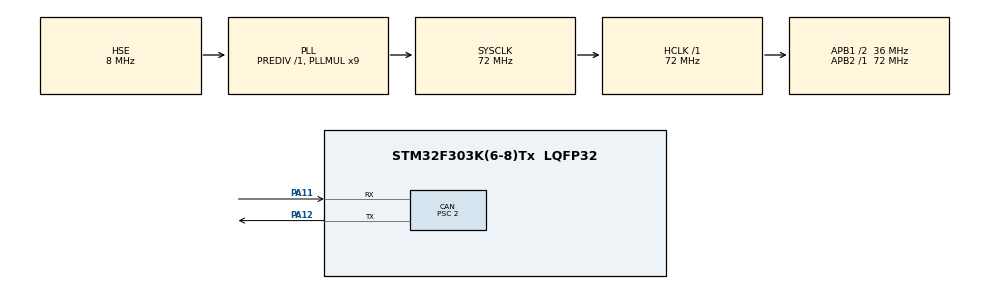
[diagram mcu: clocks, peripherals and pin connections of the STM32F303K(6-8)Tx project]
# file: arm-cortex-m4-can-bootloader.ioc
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CAN.BS1=CAN_BS1_14TQ
CAN.BS2=CAN_BS2_3TQ
CAN.CalculateBaudRate=1000000
CAN.CalculateTimeBit=1000
CAN.CalculateTimeQuantum=55.55555555555556
CAN.Prescaler=2
Mcu.Family=STM32F3
Mcu.Name=STM32F303K(6-8)Tx
Mcu.Package=LQFP32
NVIC.CAN_RX0_IRQn=true\:0\:0\:false\:false\:true\:true\:true\:true
NVIC.PriorityGroup=NVIC_PRIORITYGROUP_4
PA11.Mode=CAN_Activate
PA11.Signal=CAN_RX
PA12.Mode=CAN_Activate
PA12.Signal=CAN_TX
PA13.Mode=Serial_Wire
PA13.Signal=SYS_JTMS-SWDIO
PA14.Mode=Serial_Wire
PA14.Signal=SYS_JTCK-SWCLK
PF0\ /\ OSC_IN.Mode=HSE-External-Oscillator
PF0\ /\ OSC_IN.Signal=RCC_OSC_IN
PF1\ /\ OSC_OUT.Mode=HSE-External-Oscillator
PF1\ /\ OSC_OUT.Signal=RCC_OSC_OUT
ProjectManager.HeapSize=0x200
ProjectManager.StackSize=0x400
ProjectManager.TargetToolchain=CMake
RCC.AHBFreq_Value=72000000
RCC.APB1CLKDivider=RCC_HCLK_DIV2
RCC.APB1Freq_Value=36000000
RCC.APB1TimFreq_Value=72000000
RCC.APB2Freq_Value=72000000
RCC.APB2TimFreq_Value=72000000
RCC.CortexFreq_Value=72000000
RCC.HCLKFreq_Value=72000000
RCC.HSE_VALUE=8000000
RCC.HSI_VALUE=8000000
RCC.PLLMUL=RCC_PLL_MUL9
RCC.PLLSourceVirtual=RCC_PLLSOURCE_HSE
RCC.SYSCLKFreq_VALUE=72000000
RCC.SYSCLKSourceVirtual=RCC_SYSCLKSOURCE_PLLCLK
VP_CRC_VS_CRC.Mode=CRC_Activate
board=custom

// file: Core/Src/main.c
/* USER CODE BEGIN Header */
/**
 ******************************************************************************
 * @file           : main.c
 * @brief          : Main program body
 ******************************************************************************
 * @attention
 *
 * Copyright (c) 2026 STMicroelectronics.
 * All rights reserved.
 *
 * This software is licensed under terms that can be found in the LICENSE file
 * in the root directory of this software component.
 * If no LICENSE file comes with this software, it is provided AS-IS.
 *
 ******************************************************************************
 */
/* USER CODE END Header */
#include "main.h"

/* USER CODE BEGIN Includes */
#include "bootloader.h"
#include "can_protocol.h"
#include "stm32f3xx_it.h"
#include <stdint.h>
/* USER CODE END Includes */

CAN_HandleTypeDef hcan;

CRC_HandleTypeDef hcrc;

void SystemClock_Config(void);
static void MX_GPIO_Init(void);
static void MX_CRC_Init(void);
static void MX_CAN_Init(void);

int main(void) {

  /* MCU Configuration--------------------------------------------------------*/

  /* Reset of all peripherals, Initializes the Flash interface and the Systick.
   */
  HAL_Init();

  /* Configure the system clock */
  SystemClock_Config();

  /* Initialize all configured peripherals */
  MX_GPIO_Init();
  MX_CRC_Init();
  MX_CAN_Init();
  /* USER CODE BEGIN 2 */

  /* Variable declarations */
  static bl_state_t bl_state = BL_WAIT;
  static bl_status_t bl_status = BL_OK;
  static uint8_t bl_number_tries = 0U;
  /* Latter will be hardware coded by a unique combination of resistors (0 when
   * being pulled low, 1 pulled high), to form a combination of a 4 bits with 16
   * possible unique CAN IDs across the systems */
  const uint8_t node_id = 0x01;
  // This variable is received in the first magic frame
  static uint32_t application_size = 0;
  static uint8_t rxData[8] = {0};
  // can_protocol_configure_filters(&hcan, can_id);
  // start can peripheral
  /* USER CODE END 2 */

  /* Infinite loop */
  /* USER CODE BEGIN WHILE */
  while (1) {

    switch (bl_state) {

    case BL_WAIT:
      // TODO: Send a wake up CAN frame

      bl_status =
          bootloader_wait_for_magic_frame(&hcan, rxData, sizeof(rxData));
      if (bl_status == BL_OK) {
        // Correct frame received
        application_size =
            ((uint32_t)rxData[3] << 0U) | ((uint32_t)rxData[2] << 8U) |
            ((uint32_t)rxData[1] << 16U) | ((uint32_t)rxData[0] << 24U);

        bl_state = BL_ERASE;
      } else if (bl_status == BL_TIMEOUT) {
        // Go to application validation and jump
        bl_state = BL_JUMP;
      } else if (bl_status == BL_ERROR) {
        // Error state of the bootloader, if the system is meet in this state it
        // will need manual reset for retry
        bl_state = BL_FAILED;
      }

      bl_number_tries++;
      break;

    case BL_ERASE:

      bl_status = bootloader_erase_flash(application_size);
      if (bl_status == BL_OK) {

        // Send erase success CAN frame to flasher

        uint32_t can_id = can_protocol_format_id(
            BL_PRIORITY_ID, BL_EXT_DATA_PAGE_ID, BL_DATA_PAGE_ID,
            BL_ERASE_SUCCESS_PACKET_ID, BL_NODE_ID, BL_FLASHER_NODE_ID);

        uint8_t txData[8] = {0};

        can_protocol_send_frame(&hcan, can_id, txData);
        bl_state = BL_READY;
      }

      HAL_Delay(20);
      break;

    case BL_READY:
      // Wait for the first CAN frame from flasher
      HAL_Delay(20);
      break;

    case BL_FLASH:
      HAL_Delay(20);
      break;
    case BL_CRC:
      HAL_Delay(20);
      break;
    case BL_JUMP:

      // If application validation fails but no ERROR outside the application
      // code integrity, go back to BL_WAIT and wait there for a new flash
      HAL_Delay(20);
      break;
    case BL_FAILED:
      Error_Handler();
      break;
    default:
      break;
    }
    /* USER CODE END WHILE */

  }
}

void SystemClock_Config(void) {
  RCC_OscInitTypeDef RCC_OscInitStruct = {0};
  RCC_ClkInitTypeDef RCC_ClkInitStruct = {0};

  /** Initializes the RCC Oscillators according to the specified parameters
   * in the RCC_OscInitTypeDef structure.
   */
  RCC_OscInitStruct.OscillatorType = RCC_OSCILLATORTYPE_HSE;
  RCC_OscInitStruct.HSEState = RCC_HSE_ON;
  RCC_OscInitStruct.HSEPredivValue = RCC_HSE_PREDIV_DIV1;
  RCC_OscInitStruct.HSIState = RCC_HSI_ON;
  RCC_OscInitStruct.PLL.PLLState = RCC_PLL_ON;
  RCC_OscInitStruct.PLL.PLLSource = RCC_PLLSOURCE_HSE;
  RCC_OscInitStruct.PLL.PLLMUL = RCC_PLL_MUL9;
  if (HAL_RCC_OscConfig(&RCC_OscInitStruct) != HAL_OK) {
    Error_Handler();
  }

  /** Initializes the CPU, AHB and APB buses clocks
   */
  RCC_ClkInitStruct.ClockType = RCC_CLOCKTYPE_HCLK | RCC_CLOCKTYPE_SYSCLK |
                                RCC_CLOCKTYPE_PCLK1 | RCC_CLOCKTYPE_PCLK2;
  RCC_ClkInitStruct.SYSCLKSource = RCC_SYSCLKSOURCE_PLLCLK;
  RCC_ClkInitStruct.AHBCLKDivider = RCC_SYSCLK_DIV1;
  RCC_ClkInitStruct.APB1CLKDivider = RCC_HCLK_DIV2;
  RCC_ClkInitStruct.APB2CLKDivider = RCC_HCLK_DIV1;

  if (HAL_RCC_ClockConfig(&RCC_ClkInitStruct, FLASH_LATENCY_2) != HAL_OK) {
    Error_Handler();
  }
}

static void MX_CAN_Init(void) {

  hcan.Instance = CAN;
  hcan.Init.Prescaler = 2;
  hcan.Init.Mode = CAN_MODE_NORMAL;
  hcan.Init.SyncJumpWidth = CAN_SJW_1TQ;
  hcan.Init.TimeSeg1 = CAN_BS1_14TQ;
  hcan.Init.TimeSeg2 = CAN_BS2_3TQ;
  hcan.Init.TimeTriggeredMode = DISABLE;
  hcan.Init.AutoBusOff = DISABLE;
  hcan.Init.AutoWakeUp = DISABLE;
  hcan.Init.AutoRetransmission = DISABLE;
  hcan.Init.ReceiveFifoLocked = DISABLE;
  hcan.Init.TransmitFifoPriority = DISABLE;
  if (HAL_CAN_Init(&hcan) != HAL_OK) {
    Error_Handler();
  }
}

static void MX_CRC_Init(void) {

  hcrc.Instance = CRC;
  hcrc.Init.DefaultPolynomialUse = DEFAULT_POLYNOMIAL_ENABLE;
  hcrc.Init.DefaultInitValueUse = DEFAULT_INIT_VALUE_ENABLE;
  hcrc.Init.InputDataInversionMode = CRC_INPUTDATA_INVERSION_NONE;
  hcrc.Init.OutputDataInversionMode = CRC_OUTPUTDATA_INVERSION_DISABLE;
  hcrc.InputDataFormat = CRC_INPUTDATA_FORMAT_BYTES;
  if (HAL_CRC_Init(&hcrc) != HAL_OK) {
    Error_Handler();
  }
}

static void MX_GPIO_Init(void) {

  /* GPIO Ports Clock Enable */
  __HAL_RCC_GPIOF_CLK_ENABLE();
  __HAL_RCC_GPIOA_CLK_ENABLE();

}

void Error_Handler(void) {
  __disable_irq();
  while (1) {
  }
}
#ifdef USE_FULL_ASSERT
/**
 * @brief  Reports the name of the source file and the source line number
 *         where the assert_param error has occurred.
 * @param  file: pointer to the source file name
 * @param  line: assert_param error line source number
 * @retval None
 */
void assert_failed(uint8_t *file, uint32_t line) {
  /* USER CODE BEGIN 6 */
  /* User can add his own implementation to report the file name and line
     number, ex: printf("Wrong parameters value: file %s on line %d\r\n", file,
     line) */
  /* USER CODE END 6 */
}
#endif /* USE_FULL_ASSERT */
